# MDIO register map
Vendor: Texas Instruments
Peripheral module from a debugger description file (folder am572x).
Registers are 32-bit, access per field, reset 0x0 unless marked. A register's access mark holds for its fields unless they carry their own. Offsets are as the file gives them; lines under a group give offsets from that group; [hi:lo] are bit positions; {n}, {i} and the like mark numbered series; 'fields as' and 'values as' point back to an identical list; <NAME> marks a mode.

## MDIO
0x00 MDIO_VER rw reset not defined — MDIO Revision
  [31:0] REVISION — MDIO revision value
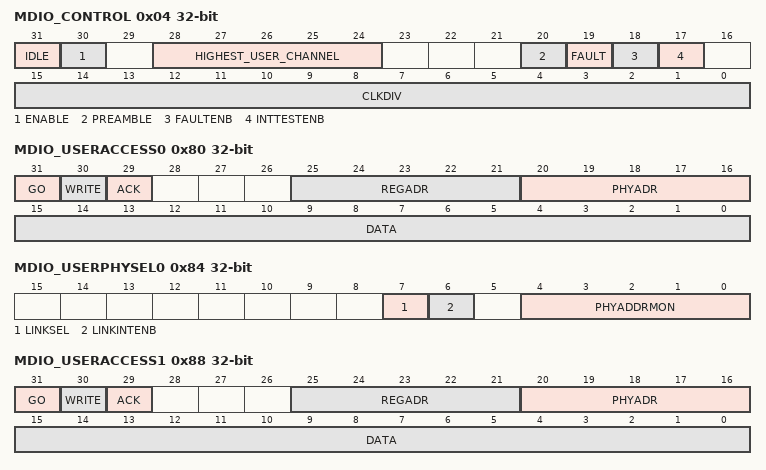
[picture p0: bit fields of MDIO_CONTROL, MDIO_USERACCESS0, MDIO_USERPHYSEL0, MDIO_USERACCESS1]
0x04 MDIO_CONTROL
  [31] IDLE ro — MDIO state machine IDLE. Set to 1 when the state machine is in the idle state. 0: State machine is not in idle state. 1: State machine is in idle state.
  [30] ENABLE rw — Enable control. If the MDIO state machine is active at the time it is disabled, it will complete the current operation before halting and setting the IDLE bit. If using byte access, the ENABLE bit has to be the last bit written in this register. 0: Disables the MDIO state machine. 1: Enable the MDIO state machine.
  [28:24] HIGHEST_USER_CHANNEL ro — Highest user channel. This field specifies the highest user access channel that is available in the module and is currently set to 1. This implies that theMDIO_USERACCESS1 register is the highest available user access channel.
  [20] PREAMBLE rw — Preamble disable. 0: Standard MDIO preamble is used. 1: Disables this device from sending MDIO frame preambles.
  [19] FAULT rw — Fault indicator. This bit is set to 1 if the MDIO pins fail to read back what the device is driving onto them. This indicates a physical layer fault and the module state machine is reset. Writing a 1 to it clears this bit. 0: No failure. 1: Physical layer fault; the MDIO state machine is reset.
  [18] FAULTENB rw — Fault detect enable. This bit has to be set to 1 to enable the physical layer fault detection. 0: Disables the physical layer fault detection. 1: Enables the physical layer fault detection.
  [17] INTTESTENB rw — Interrupt test enable. This bit can be set to 1 to enable the host to set the USERINT and LINKINT bits for test purposes. 0: Interrupt bits are not set. 1: Enables the host to set the USERINT and LINKINT bits for test purposes.
  [15:0] CLKDIV rw — Clock divider. This field specifies the division ratio between ICLK and the frequency of MDCLK. MDCLK is disabled when CLKDIV is set to 0. MDCLK frequency = ICLK frequency/(CLKDIV+1).
0x08 MDIO_ALIVE rw — PHY Alive Status Register
  [31:0] ALIVE — MDIO alive. Each of the 32 bits of this register is set if the most recent access to the PHY with address corresponding to the register bit number was acknowledged by the PHY, the bit is reset if the PHY fails to acknowledge the access. Both the user and polling accesses to a PHY will cause the corresponding alive bit to be updated. The alive bits are only meant to be used to give an indication of the presence or not of a PHY with the corresponding address. Writing a 1 to any bit will clear it, writing a 0 has no effect.
0x0C MDIO_LINK ro — PHY Link Status
  [31:0] LINK — MDIO link state. This register is updated after a read of the Generic Status Register of a PHY. The bit is set if the PHY with the corresponding address has link and the PHY acknowledges the read transaction. The bit is reset if the PHY indicates it does not have link or fails to acknowledge the read transaction. Writes to the register have no effect. In addition, the status of the two PHYs specified in the MDIO_USERPHYSEL registers can be determined using the MLINK input pins (NOT PINNED OUT). This is determined by the LINKSEL bit in the MDIO_USERPHYSEL register.
0x10 MDIO_LINKINTRAW
  [1:0] LINKINTRAW rw — MDIO link change event, raw value.
0x14 MDIO_LINKINTMASKED — MDIO Link Status Change Interrupt Register
  [1:0] LINKINTMASKED rw — MDIO link change interrupt, masked value. When asserted 1, a bit indicates that there was an MDIO link change event (i.e. change in the MDIO Link register) corresponding to the PHY address in the MDIO_USERPHYSEL register and the corresponding LINKINTENB bit was set. LINKINTMASKED[0] and LINKINTMASKED[1] correspond toMDIO_USERPHYSEL0 and MDIO_USERPHYSEL1, respectively. Writing a 1 will clear the interrupt and writing 0 has no effect. If the INTTESTENB bit in the MDIO_CONTROL register is set, the host may set the LINKINT bits to a 1. This mode may be used for test purposes.
0x20 MDIO_USERINTRAW — MDIO User Command Complete Interrupt
  [1:0] USERINTRAW rw — Raw value of MDIO user command complete event for theMDIO_USERACCESS1 and MDIO_USERACCESS0 register, respectively. When asserted 1, a bit indicates that the previously scheduled PHY read or write command using that particular MDIO_USERACCESS register has completed. Writing a 1 will clear the event and writing 0 has no effect. If the INTTESTENB bit in the MDIO_CONTROL register is set, the host may set the USERINTRAW bits to a 1. This mode may be used for test purposes.
0x24 MDIO_USERINTMASKED — MDIO User Command Complete Interrupt
  [1:0] USERINTMASKED rw — Masked value of MDIO user command complete interrupt for theMDIO_USERACCESS1 and MDIO_USERACCESS0 register, respectively. When asserted 1, a bit indicates that the previously scheduled PHY read or write command using that particular MDIO_USERACCESS register has completed and the corresponding USERINTMASKSET bit is set to 1. Writing a 1 will clear the interrupt and writing 0 has no effect. If the INTTESTENB bit in the MDIO_CONTROL register is set, the host may set the USERINTMASKED bits to a 1. This mode may be used for test purposes.
0x28 MDIO_USERINTMASKSET — MDIO User Command Complete Interrupt Mask Set
  [1:0] USERINTMASKSET rw — MDIO user interrupt mask set for USERINTMASKED[1:0], respectively. Writing a bit to 1 will enable MDIO user command complete interrupts for that particular MDIO_USERACCESS register. MDIO user interrupt for a particular MDIO_USERACCESS register is disabled if the corresponding bit is 0. Writing a 0 to this register has no effect.
0x2C MDIO_USERINTMASKCLR — MDIO User Command Complete Interrupt Mask Clear
  [1:0] USERINTMASKCLEAR rw — MDIO user command complete interrupt mask clear for USERINTMASKED[1:0], respectively. Writing a bit to 1 will disable further user command complete interrupts for that particular MDIO_USERACCESS register. Writing a 0 to this register has no effect.
0x80 MDIO_USERACCESS0 — MDIO_User_Access
  [31] GO rw — Go. Writing a 1 to this bit causes the MDIO state machine to perform an MDIO access when it is convenient for it to do so, this is not an instantaneous process. Writing a 0 to this bit has no effect. This bit is write able only if the MDIO state machine is enabled. This bit will self clear when the requested access has been completed. Any writes to theMDIO_USERACCESS0 register are blocked when the GO bit is 1. If byte access is being used, the GO bit should be written last.
  [30] WRITE rw — Write enable. Setting this bit to a 1 causes the MDIO transaction to be a register write, otherwise it is a register read.
  [29] ACK rw — Acknowledge. This bit is set if the PHY acknowledged the read transaction.
  [25:21] REGADR rw — Register address. Specifies the PHY register to be accessed for this transaction.
  [20:16] PHYADR rw — PHY address. Specifies the PHY to be accesses for this transaction.
  [15:0] DATA rw — User data. The data value read from or to be written to the specified PHY register.
0x84 MDIO_USERPHYSEL0 — MDIO User PHY Select
  [7] LINKSEL rw — Link status determination select. Set to 1 to determine link status using the MLINK pin (NOT PINNED OUT). Default value is 0 which implies that the link status is determined by the MDIO state machine.
  [6] LINKINTENB rw — Link change interrupt enable. Set to 1 to enable link change status interrupts for PHY address specified in PHYADDRMON. Link change interrupts are disabled if this bit is set to 0. 0: Link change interrupts are disabled. 1: Link change status interrupts for PHY address specified in PHYADDRMON bits are enabled.
  [4:0] PHYADDRMON rw — PHY address whose link status is to be monitored.
0x88 MDIO_USERACCESS1 — MDIO User Access
  [31] GO rw — Go. Writing a 1 to this bit causes the MDIO state machine to perform an MDIO access when it is convenient for it to do so, this is not an instantaneous process. Writing a 0 to this bit has no effect. This bit is write able only if the MDIO state machine is enabled. This bit will self clear when the requested access has been completed. Any writes to theMDIO_USERACCESS1 register are blocked when the GO bit is 1. If byte access is being used, the GO bit should be written last.
  [30] WRITE rw — Write enable. Setting this bit to a 1 causes the MDIO transaction to be a register write, otherwise it is a register read.
  [29] ACK rw — Acknowledge. This bit is set if the PHY acknowledged the read transaction.
  [25:21] REGADR rw — Register address. Specifies the PHY register to be accessed for this transaction.
  [20:16] PHYADR rw — PHY address. Specifies the PHY to be accesses for this transaction.
  [15:0] DATA rw — User data. The data value read from or to be written to the specified PHY register.
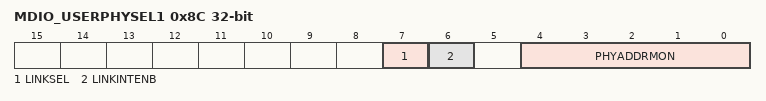
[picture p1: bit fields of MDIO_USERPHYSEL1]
0x8C MDIO_USERPHYSEL1 — MDIO User PHY Select
  fields as MDIO_USERPHYSEL0
